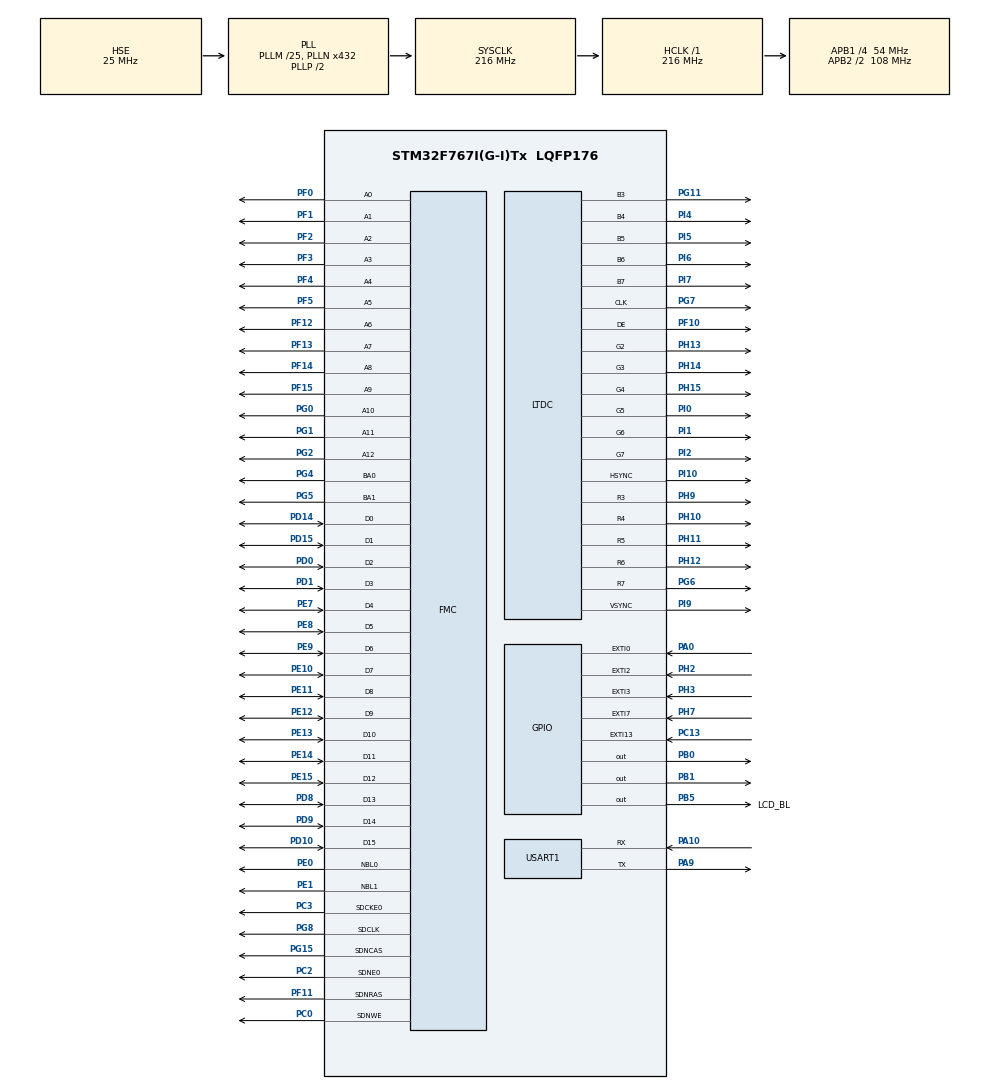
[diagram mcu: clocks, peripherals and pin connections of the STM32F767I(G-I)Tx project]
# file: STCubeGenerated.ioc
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CORTEX_M7.AccessPermission-Cortex_Memory_Protection_Unit_Region0_Settings=MPU_REGION_FULL_ACCESS
CORTEX_M7.BaseAddress-Cortex_Memory_Protection_Unit_Region0_Settings=0x60000000
CORTEX_M7.CPU_DCache=Enabled
CORTEX_M7.CPU_ICache=Enabled
CORTEX_M7.Enable-Cortex_Memory_Protection_Unit_Region0_Settings=MPU_REGION_ENABLE
CORTEX_M7.FlashInterface=TCM_Enabled
CORTEX_M7.IsBufferable-Cortex_Memory_Protection_Unit_Region0_Settings=MPU_ACCESS_BUFFERABLE
CORTEX_M7.MPU_Control=MPU_PRIVILEGED_DEFAULT
CORTEX_M7.Size-Cortex_Memory_Protection_Unit_Region0_Settings=MPU_REGION_SIZE_256MB
FMC.CASLatency1=FMC_SDRAM_CAS_LATENCY_3
FMC.ColumnBitsNumber1=FMC_SDRAM_COLUMN_BITS_NUM_9
FMC.ExitSelfRefreshDelay1=8
FMC.LoadToActiveDelay1=2
FMC.RCDDelay1=4
FMC.RPDelay1=2
FMC.ReadBurst1=FMC_SDRAM_RBURST_ENABLE
FMC.ReadPipeDelay1=FMC_SDRAM_RPIPE_DELAY_0
FMC.RowCycleDelay1=5
FMC.RowCycleDelay2=5
FMC.SDClockPeriod1=FMC_SDRAM_CLOCK_PERIOD_2
FMC.SelfRefreshTime1=6
FMC.WriteRecoveryTime1=2
LTDC.ActiveH=LCD_HEIGHT
LTDC.ActiveW=LCD_WIDTH
LTDC.Alpha_L0=255
LTDC.FBStartAdress_L0=LAYER0_ADDR
LTDC.FBStartAdress_L1=LAYER1_ADDR
LTDC.HBP=40
LTDC.HFP=5
LTDC.HSync=1
LTDC.ImageHeight_L0=LCD_HEIGHT
LTDC.ImageHeight_L1=LCD_HEIGHT
LTDC.ImageWidth_L0=LCD_WIDTH
LTDC.ImageWidth_L1=LCD_WIDTH
LTDC.Layers=1
LTDC.PixelFormat_L0=LTDC_PIXEL_FORMAT_RGB565
LTDC.PixelFormat_L1=LTDC_PIXEL_FORMAT_RGB565
LTDC.VBP=8
LTDC.VFP=8
LTDC.VSync=1
LTDC.WindowX1_L0=LCD_WIDTH
LTDC.WindowX1_L1=LCD_WIDTH
LTDC.WindowY1_L0=LCD_HEIGHT
LTDC.WindowY1_L1=LCD_HEIGHT
Mcu.Family=STM32F7
Mcu.Name=STM32F767I(G-I)Tx
Mcu.Package=LQFP176
Mcu.UserConstants=LAYER1_ADDR,0xC003FC00;LAYER0_ADDR,0xC0000000;LCD_WIDTH,480;LCD_HEIGHT,272
NVIC.EXTI0_IRQn=true\:0\:0\:false\:false\:true\:true\:true
NVIC.EXTI15_10_IRQn=true\:0\:0\:false\:false\:true\:true\:true
NVIC.EXTI2_IRQn=true\:0\:0\:false\:false\:true\:true\:true
NVIC.EXTI3_IRQn=true\:0\:0\:false\:false\:true\:true\:true
NVIC.EXTI9_5_IRQn=true\:0\:0\:false\:false\:true\:true\:true
NVIC.PriorityGroup=NVIC_PRIORITYGROUP_4
NVIC.USART1_IRQn=true\:0\:0\:false\:false\:true\:true\:true
PA0/WKUP.GPIO_PuPd=GPIO_PULLDOWN
PA0/WKUP.Signal=GPXTI0
PA10.Mode=Asynchronous
PA10.Signal=USART1_RX
PA13.Mode=Serial_Wire
PA13.Signal=SYS_JTMS-SWDIO
PA14.Mode=Serial_Wire
PA14.Signal=SYS_JTCK-SWCLK
PA9.Mode=Asynchronous
PA9.Signal=USART1_TX
PB0.Signal=GPIO_Output
PB1.Signal=GPIO_Output
PB5.GPIO_Label=LCD_BL
PB5.GPIO_Speed=GPIO_SPEED_FREQ_LOW
PB5.PinState=GPIO_PIN_SET
PB5.Signal=GPIO_Output
PC0.Signal=FMC_SDNWE
PC13.GPIO_ModeDefaultEXTI=GPIO_MODE_IT_FALLING
PC13.GPIO_PuPd=GPIO_PULLUP
PC13.Signal=GPXTI13
PC2.Mode=SdramChipSelect1_1
PC2.Signal=FMC_SDNE0
PC3.Mode=SdramChipSelect1_1
PC3.Signal=FMC_SDCKE0
PD0.Signal=FMC_D2_DA2
PD1.Signal=FMC_D3_DA3
PD10.Signal=FMC_D15_DA15
PD14.Signal=FMC_D0_DA0
PD15.Signal=FMC_D1_DA1
PD8.Signal=FMC_D13_DA13
PD9.Signal=FMC_D14_DA14
PE0.Signal=FMC_NBL0
PE1.Signal=FMC_NBL1
PE10.Signal=FMC_D7_DA7
PE11.Signal=FMC_D8_DA8
PE12.Signal=FMC_D9_DA9
PE13.Signal=FMC_D10_DA10
PE14.Signal=FMC_D11_DA11
PE15.Signal=FMC_D12_DA12
PE7.Signal=FMC_D4_DA4
PE8.Signal=FMC_D5_DA5
PE9.Signal=FMC_D6_DA6
PF0.Signal=FMC_A0
PF1.Signal=FMC_A1
PF10.GPIO_Speed=GPIO_SPEED_FREQ_VERY_HIGH
PF10.Mode=RGB565
PF10.Signal=LTDC_DE
PF11.Signal=FMC_SDNRAS
PF12.Signal=FMC_A6
PF13.Signal=FMC_A7
PF14.Signal=FMC_A8
PF15.Signal=FMC_A9
PF2.Signal=FMC_A2
PF3.Signal=FMC_A3
PF4.Signal=FMC_A4
PF5.Signal=FMC_A5
PG0.Signal=FMC_A10
PG1.Signal=FMC_A11
PG11.GPIO_Speed=GPIO_SPEED_FREQ_VERY_HIGH
PG11.Mode=RGB565
PG11.Signal=LTDC_B3
PG15.Signal=FMC_SDNCAS
PG2.Signal=FMC_A12
PG4.Signal=FMC_A14_BA0
PG5.Signal=FMC_A15_BA1
PG6.GPIO_Speed=GPIO_SPEED_FREQ_VERY_HIGH
PG6.Mode=RGB565
PG6.Signal=LTDC_R7
PG7.GPIO_Speed=GPIO_SPEED_FREQ_VERY_HIGH
PG7.Mode=RGB565
PG7.Signal=LTDC_CLK
PG8.Signal=FMC_SDCLK
PH0/OSC_IN.Mode=HSE-External-Oscillator
PH0/OSC_IN.Signal=RCC_OSC_IN
PH1/OSC_OUT.Mode=HSE-External-Oscillator
PH1/OSC_OUT.Signal=RCC_OSC_OUT
PH10.GPIO_Speed=GPIO_SPEED_FREQ_VERY_HIGH
PH10.Mode=RGB565
PH10.Signal=LTDC_R4
PH11.GPIO_Speed=GPIO_SPEED_FREQ_VERY_HIGH
PH11.Mode=RGB565
PH11.Signal=LTDC_R5
PH12.GPIO_Speed=GPIO_SPEED_FREQ_VERY_HIGH
PH12.Mode=RGB565
PH12.Signal=LTDC_R6
PH13.GPIO_Speed=GPIO_SPEED_FREQ_VERY_HIGH
PH13.Mode=RGB565
PH13.Signal=LTDC_G2
PH14.GPIO_Speed=GPIO_SPEED_FREQ_VERY_HIGH
PH14.Mode=RGB565
PH14.Signal=LTDC_G3
PH15.GPIO_Speed=GPIO_SPEED_FREQ_VERY_HIGH
PH15.Mode=RGB565
PH15.Signal=LTDC_G4
PH2.GPIO_ModeDefaultEXTI=GPIO_MODE_IT_FALLING
PH2.GPIO_PuPd=GPIO_PULLUP
PH2.Signal=GPXTI2
PH3.GPIO_ModeDefaultEXTI=GPIO_MODE_IT_FALLING
PH3.GPIO_PuPd=GPIO_PULLUP
PH3.Signal=GPXTI3
PH7.GPIO_ModeDefaultEXTI=GPIO_MODE_IT_FALLING
PH7.Signal=GPXTI7
PH9.GPIO_Speed=GPIO_SPEED_FREQ_VERY_HIGH
PH9.Mode=RGB565
PH9.Signal=LTDC_R3
PI0.GPIO_Speed=GPIO_SPEED_FREQ_VERY_HIGH
PI0.Mode=RGB565
PI0.Signal=LTDC_G5
PI1.GPIO_Speed=GPIO_SPEED_FREQ_VERY_HIGH
PI1.Mode=RGB565
PI1.Signal=LTDC_G6
PI10.GPIO_Speed=GPIO_SPEED_FREQ_VERY_HIGH
PI10.Mode=RGB565
PI10.Signal=LTDC_HSYNC
PI2.GPIO_Speed=GPIO_SPEED_FREQ_VERY_HIGH
PI2.Mode=RGB565
PI2.Signal=LTDC_G7
PI4.GPIO_Speed=GPIO_SPEED_FREQ_VERY_HIGH
PI4.Mode=RGB565
PI4.Signal=LTDC_B4
PI5.GPIO_Speed=GPIO_SPEED_FREQ_VERY_HIGH
PI5.Mode=RGB565
PI5.Signal=LTDC_B5
PI6.GPIO_Speed=GPIO_SPEED_FREQ_VERY_HIGH
PI6.Mode=RGB565
PI6.Signal=LTDC_B6
PI7.GPIO_Speed=GPIO_SPEED_FREQ_VERY_HIGH
PI7.Mode=RGB565
PI7.Signal=LTDC_B7
PI9.GPIO_Speed=GPIO_SPEED_FREQ_VERY_HIGH
PI9.Mode=RGB565
PI9.Signal=LTDC_VSYNC
ProjectManager.HeapSize=0x200
ProjectManager.StackSize=0x400
ProjectManager.TargetToolchain=Other Toolchains (GPDSC)
RCC.AHBFreq_Value=216000000
RCC.APB1CLKDivider=RCC_HCLK_DIV4
RCC.APB1Freq_Value=54000000
RCC.APB1TimFreq_Value=108000000
RCC.APB2CLKDivider=RCC_HCLK_DIV2
RCC.APB2Freq_Value=108000000
RCC.APB2TimFreq_Value=216000000
RCC.CortexFreq_Value=216000000
RCC.EnbaleCSS=true
RCC.HCLKFreq_Value=216000000
RCC.HSE_VALUE=25000000
RCC.HSI_VALUE=16000000
RCC.LSE_VALUE=32768
RCC.PLLM=25
RCC.PLLN=432
RCC.PLLSAIN=288
RCC.PLLSAIR=4
RCC.PLLSAIRDiv=RCC_PLLSAIDIVR_8
RCC.PLLSourceVirtual=RCC_PLLSOURCE_HSE
RCC.SYSCLKFreq_VALUE=216000000
RCC.SYSCLKSource=RCC_SYSCLKSOURCE_PLLCLK
RCC.USBFreq_Value=216000000
RCC.VCOOutputFreq_Value=432000000
SH.FMC_A0.0=FMC_A0,13b-sda1
SH.FMC_A1.0=FMC_A1,13b-sda1
SH.FMC_A10.0=FMC_A10,13b-sda1
SH.FMC_A11.0=FMC_A11,13b-sda1
SH.FMC_A12.0=FMC_A12,13b-sda1
SH.FMC_A14_BA0.0=FMC_BA0,FourSdramBanks1
SH.FMC_A15_BA1.0=FMC_BA1,FourSdramBanks1
SH.FMC_A2.0=FMC_A2,13b-sda1
SH.FMC_A3.0=FMC_A3,13b-sda1
SH.FMC_A4.0=FMC_A4,13b-sda1
SH.FMC_A5.0=FMC_A5,13b-sda1
SH.FMC_A6.0=FMC_A6,13b-sda1
SH.FMC_A7.0=FMC_A7,13b-sda1
SH.FMC_A8.0=FMC_A8,13b-sda1
SH.FMC_A9.0=FMC_A9,13b-sda1
SH.FMC_D0_DA0.0=FMC_D0,sd-16b-d1
SH.FMC_D10_DA10.0=FMC_D10,sd-16b-d1
SH.FMC_D11_DA11.0=FMC_D11,sd-16b-d1
SH.FMC_D12_DA12.0=FMC_D12,sd-16b-d1
SH.FMC_D13_DA13.0=FMC_D13,sd-16b-d1
SH.FMC_D14_DA14.0=FMC_D14,sd-16b-d1
SH.FMC_D15_DA15.0=FMC_D15,sd-16b-d1
SH.FMC_D1_DA1.0=FMC_D1,sd-16b-d1
SH.FMC_D2_DA2.0=FMC_D2,sd-16b-d1
SH.FMC_D3_DA3.0=FMC_D3,sd-16b-d1
SH.FMC_D4_DA4.0=FMC_D4,sd-16b-d1
SH.FMC_D5_DA5.0=FMC_D5,sd-16b-d1
SH.FMC_D6_DA6.0=FMC_D6,sd-16b-d1
SH.FMC_D7_DA7.0=FMC_D7,sd-16b-d1
SH.FMC_D8_DA8.0=FMC_D8,sd-16b-d1
SH.FMC_D9_DA9.0=FMC_D9,sd-16b-d1
SH.FMC_NBL0.0=FMC_NBL0,Sd2ByteEnable1
SH.FMC_NBL1.0=FMC_NBL1,Sd2ByteEnable1
SH.FMC_SDCLK.0=FMC_SDCLK,13b-sda1
SH.FMC_SDNCAS.0=FMC_SDNCAS,13b-sda1
SH.FMC_SDNRAS.0=FMC_SDNRAS,13b-sda1
SH.FMC_SDNWE.0=FMC_SDNWE,13b-sda1
USART1.VirtualMode-Asynchronous=VM_ASYNC
VP_CRC_VS_CRC.Mode=CRC_Activate
board=custom

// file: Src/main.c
/* USER CODE BEGIN Header */
/**
  ******************************************************************************
  * @file           : main.c
  * @brief          : Main program body
  ******************************************************************************
  * @attention
  *
  * <h2><center>&copy; Copyright (c) 2019 STMicroelectronics.
  * All rights reserved.</center></h2>
  *
  * This software component is licensed by ST under BSD 3-Clause license,
  * the "License"; You may not use this file except in compliance with the
  * License. You may obtain a copy of the License at:
  *                        opensource.org/licenses/BSD-3-Clause
  *
  ******************************************************************************
  */
/* USER CODE END Header */

#include "main.h"

CRC_HandleTypeDef hcrc;

LTDC_HandleTypeDef hltdc;

UART_HandleTypeDef huart1;

SDRAM_HandleTypeDef hsdram1;

void SystemClock_Config(void);
static void MPU_Config(void);
static void MX_GPIO_Init(void);
static void MX_USART1_UART_Init(void);
static void MX_CRC_Init(void);
static void MX_FMC_Init(void);
static void MX_LTDC_Init(void);

int main(void)
{

  /* MPU Configuration--------------------------------------------------------*/
  MPU_Config();

  /* Enable I-Cache---------------------------------------------------------*/
  SCB_EnableICache();

  /* Enable D-Cache---------------------------------------------------------*/
  SCB_EnableDCache();

  /* MCU Configuration--------------------------------------------------------*/

  /* Reset of all peripherals, Initializes the Flash interface and the Systick. */
  HAL_Init();

  /* USER CODE BEGIN Init */
  SCB->CACR |= 1<<2;   //强制D-Cache透写,如不开启,实际使用中可能遇到各种问题
  /* USER CODE END Init */

  /* Configure the system clock */
  SystemClock_Config();

  /* Initialize all configured peripherals */
  MX_GPIO_Init();
  MX_USART1_UART_Init();
  MX_CRC_Init();
  MX_FMC_Init();
  MX_LTDC_Init();
  /* USER CODE BEGIN 2 */
  os_init();
  /* USER CODE END 2 */

  /* Infinite loop */
  while (1)
  {

  }
}

void SystemClock_Config(void)
{
  RCC_OscInitTypeDef RCC_OscInitStruct = {0};
  RCC_ClkInitTypeDef RCC_ClkInitStruct = {0};
  RCC_PeriphCLKInitTypeDef PeriphClkInitStruct = {0};

  /** Configure the main internal regulator output voltage
  */
  __HAL_RCC_PWR_CLK_ENABLE();
  __HAL_PWR_VOLTAGESCALING_CONFIG(PWR_REGULATOR_VOLTAGE_SCALE1);
  /** Initializes the CPU, AHB and APB busses clocks
  */
  RCC_OscInitStruct.OscillatorType = RCC_OSCILLATORTYPE_HSE;
  RCC_OscInitStruct.HSEState = RCC_HSE_ON;
  RCC_OscInitStruct.PLL.PLLState = RCC_PLL_ON;
  RCC_OscInitStruct.PLL.PLLSource = RCC_PLLSOURCE_HSE;
  RCC_OscInitStruct.PLL.PLLM = 25;
  RCC_OscInitStruct.PLL.PLLN = 432;
  RCC_OscInitStruct.PLL.PLLP = RCC_PLLP_DIV2;
  RCC_OscInitStruct.PLL.PLLQ = 2;
  if (HAL_RCC_OscConfig(&RCC_OscInitStruct) != HAL_OK)
  {
    Error_Handler();
  }
  /** Activate the Over-Drive mode
  */
  if (HAL_PWREx_EnableOverDrive() != HAL_OK)
  {
    Error_Handler();
  }
  /** Initializes the CPU, AHB and APB busses clocks
  */
  RCC_ClkInitStruct.ClockType = RCC_CLOCKTYPE_HCLK|RCC_CLOCKTYPE_SYSCLK
                              |RCC_CLOCKTYPE_PCLK1|RCC_CLOCKTYPE_PCLK2;
  RCC_ClkInitStruct.SYSCLKSource = RCC_SYSCLKSOURCE_PLLCLK;
  RCC_ClkInitStruct.AHBCLKDivider = RCC_SYSCLK_DIV1;
  RCC_ClkInitStruct.APB1CLKDivider = RCC_HCLK_DIV4;
  RCC_ClkInitStruct.APB2CLKDivider = RCC_HCLK_DIV2;

  if (HAL_RCC_ClockConfig(&RCC_ClkInitStruct, FLASH_LATENCY_7) != HAL_OK)
  {
    Error_Handler();
  }
  PeriphClkInitStruct.PeriphClockSelection = RCC_PERIPHCLK_LTDC|RCC_PERIPHCLK_USART1;
  PeriphClkInitStruct.PLLSAI.PLLSAIN = 288;
  PeriphClkInitStruct.PLLSAI.PLLSAIR = 4;
  PeriphClkInitStruct.PLLSAI.PLLSAIQ = 2;
  PeriphClkInitStruct.PLLSAI.PLLSAIP = RCC_PLLSAIP_DIV2;
  PeriphClkInitStruct.PLLSAIDivQ = 1;
  PeriphClkInitStruct.PLLSAIDivR = RCC_PLLSAIDIVR_8;
  PeriphClkInitStruct.Usart1ClockSelection = RCC_USART1CLKSOURCE_PCLK2;
  if (HAL_RCCEx_PeriphCLKConfig(&PeriphClkInitStruct) != HAL_OK)
  {
    Error_Handler();
  }
  /** Enables the Clock Security System
  */
  HAL_RCC_EnableCSS();
}

static void MX_CRC_Init(void)
{

  hcrc.Instance = CRC;
  hcrc.Init.DefaultPolynomialUse = DEFAULT_POLYNOMIAL_ENABLE;
  hcrc.Init.DefaultInitValueUse = DEFAULT_INIT_VALUE_ENABLE;
  hcrc.Init.InputDataInversionMode = CRC_INPUTDATA_INVERSION_NONE;
  hcrc.Init.OutputDataInversionMode = CRC_OUTPUTDATA_INVERSION_DISABLE;
  hcrc.InputDataFormat = CRC_INPUTDATA_FORMAT_BYTES;
  if (HAL_CRC_Init(&hcrc) != HAL_OK)
  {
    Error_Handler();
  }

}

static void MX_LTDC_Init(void)
{

  LTDC_LayerCfgTypeDef pLayerCfg = {0};
  LTDC_LayerCfgTypeDef pLayerCfg1 = {0};

  hltdc.Instance = LTDC;
  hltdc.Init.HSPolarity = LTDC_HSPOLARITY_AL;
  hltdc.Init.VSPolarity = LTDC_VSPOLARITY_AL;
  hltdc.Init.DEPolarity = LTDC_DEPOLARITY_AL;
  hltdc.Init.PCPolarity = LTDC_PCPOLARITY_IPC;
  hltdc.Init.HorizontalSync = 0;
  hltdc.Init.VerticalSync = 0;
  hltdc.Init.AccumulatedHBP = 40;
  hltdc.Init.AccumulatedVBP = 8;
  hltdc.Init.AccumulatedActiveW = 520;
  hltdc.Init.AccumulatedActiveH = 280;
  hltdc.Init.TotalWidth = 525;
  hltdc.Init.TotalHeigh = 288;
  hltdc.Init.Backcolor.Blue = 0;
  hltdc.Init.Backcolor.Green = 0;
  hltdc.Init.Backcolor.Red = 0;
  if (HAL_LTDC_Init(&hltdc) != HAL_OK)
  {
    Error_Handler();
  }
  pLayerCfg.WindowX0 = 0;
  pLayerCfg.WindowX1 = LCD_WIDTH;
  pLayerCfg.WindowY0 = 0;
  pLayerCfg.WindowY1 = LCD_HEIGHT;
  pLayerCfg.PixelFormat = LTDC_PIXEL_FORMAT_RGB565;
  pLayerCfg.Alpha = 255;
  pLayerCfg.Alpha0 = 0;
  pLayerCfg.BlendingFactor1 = LTDC_BLENDING_FACTOR1_CA;
  pLayerCfg.BlendingFactor2 = LTDC_BLENDING_FACTOR2_CA;
  pLayerCfg.FBStartAdress = LAYER0_ADDR;
  pLayerCfg.ImageWidth = LCD_WIDTH;
  pLayerCfg.ImageHeight = LCD_HEIGHT;
  pLayerCfg.Backcolor.Blue = 0;
  pLayerCfg.Backcolor.Green = 0;
  pLayerCfg.Backcolor.Red = 0;
  if (HAL_LTDC_ConfigLayer(&hltdc, &pLayerCfg, 0) != HAL_OK)
  {
    Error_Handler();
  }
  pLayerCfg1.WindowX0 = 0;
  pLayerCfg1.WindowX1 = LCD_WIDTH;
  pLayerCfg1.WindowY0 = 0;
  pLayerCfg1.WindowY1 = LCD_HEIGHT;
  pLayerCfg1.PixelFormat = LTDC_PIXEL_FORMAT_ARGB8888;
  pLayerCfg1.Alpha = 0;
  pLayerCfg1.Alpha0 = 0;
  pLayerCfg1.BlendingFactor1 = LTDC_BLENDING_FACTOR1_CA;
  pLayerCfg1.BlendingFactor2 = LTDC_BLENDING_FACTOR2_CA;
  pLayerCfg1.FBStartAdress = LAYER1_ADDR;
  pLayerCfg1.ImageWidth = LCD_WIDTH;
  pLayerCfg1.ImageHeight = LCD_HEIGHT;
  pLayerCfg1.Backcolor.Blue = 0;
  pLayerCfg1.Backcolor.Green = 0;
  pLayerCfg1.Backcolor.Red = 0;
  if (HAL_LTDC_ConfigLayer(&hltdc, &pLayerCfg1, 1) != HAL_OK)
  {
    Error_Handler();
  }

}

static void MX_USART1_UART_Init(void)
{

  huart1.Instance = USART1;
  huart1.Init.BaudRate = 115200;
  huart1.Init.WordLength = UART_WORDLENGTH_8B;
  huart1.Init.StopBits = UART_STOPBITS_1;
  huart1.Init.Parity = UART_PARITY_NONE;
  huart1.Init.Mode = UART_MODE_TX_RX;
  huart1.Init.HwFlowCtl = UART_HWCONTROL_NONE;
  huart1.Init.OverSampling = UART_OVERSAMPLING_16;
  huart1.Init.OneBitSampling = UART_ONE_BIT_SAMPLE_DISABLE;
  huart1.AdvancedInit.AdvFeatureInit = UART_ADVFEATURE_NO_INIT;
  if (HAL_UART_Init(&huart1) != HAL_OK)
  {
    Error_Handler();
  }

}

/* FMC initialization function */
static void MX_FMC_Init(void)
{

  FMC_SDRAM_TimingTypeDef SdramTiming = {0};

  /** Perform the SDRAM1 memory initialization sequence
  */
  hsdram1.Instance = FMC_SDRAM_DEVICE;
  /* hsdram1.Init */
  hsdram1.Init.SDBank = FMC_SDRAM_BANK1;
  hsdram1.Init.ColumnBitsNumber = FMC_SDRAM_COLUMN_BITS_NUM_9;
  hsdram1.Init.RowBitsNumber = FMC_SDRAM_ROW_BITS_NUM_13;
  hsdram1.Init.MemoryDataWidth = FMC_SDRAM_MEM_BUS_WIDTH_16;
  hsdram1.Init.InternalBankNumber = FMC_SDRAM_INTERN_BANKS_NUM_4;
  hsdram1.Init.CASLatency = FMC_SDRAM_CAS_LATENCY_3;
  hsdram1.Init.WriteProtection = FMC_SDRAM_WRITE_PROTECTION_DISABLE;
  hsdram1.Init.SDClockPeriod = FMC_SDRAM_CLOCK_PERIOD_2;
  hsdram1.Init.ReadBurst = FMC_SDRAM_RBURST_ENABLE;
  hsdram1.Init.ReadPipeDelay = FMC_SDRAM_RPIPE_DELAY_0;
  /* SdramTiming */
  SdramTiming.LoadToActiveDelay = 2;
  SdramTiming.ExitSelfRefreshDelay = 8;
  SdramTiming.SelfRefreshTime = 6;
  SdramTiming.RowCycleDelay = 5;
  SdramTiming.WriteRecoveryTime = 2;
  SdramTiming.RPDelay = 2;
  SdramTiming.RCDDelay = 4;

  if (HAL_SDRAM_Init(&hsdram1, &SdramTiming) != HAL_OK)
  {
    Error_Handler( );
  }

}

static void MX_GPIO_Init(void)
{
  GPIO_InitTypeDef GPIO_InitStruct = {0};

  /* GPIO Ports Clock Enable */
  __HAL_RCC_GPIOC_CLK_ENABLE();
  __HAL_RCC_GPIOI_CLK_ENABLE();
  __HAL_RCC_GPIOF_CLK_ENABLE();
  __HAL_RCC_GPIOH_CLK_ENABLE();
  __HAL_RCC_GPIOA_CLK_ENABLE();
  __HAL_RCC_GPIOB_CLK_ENABLE();
  __HAL_RCC_GPIOG_CLK_ENABLE();
  __HAL_RCC_GPIOE_CLK_ENABLE();
  __HAL_RCC_GPIOD_CLK_ENABLE();

  /*Configure GPIO pin Output Level */
  HAL_GPIO_WritePin(GPIOB, GPIO_PIN_0|GPIO_PIN_1, GPIO_PIN_RESET);

  /*Configure GPIO pin Output Level */
  HAL_GPIO_WritePin(LCD_BL_GPIO_Port, LCD_BL_Pin, GPIO_PIN_SET);

  /*Configure GPIO pin : PC13 */
  GPIO_InitStruct.Pin = GPIO_PIN_13;
  GPIO_InitStruct.Mode = GPIO_MODE_IT_FALLING;
  GPIO_InitStruct.Pull = GPIO_PULLUP;
  HAL_GPIO_Init(GPIOC, &GPIO_InitStruct);

  /*Configure GPIO pin : PA0 */
  GPIO_InitStruct.Pin = GPIO_PIN_0;
  GPIO_InitStruct.Mode = GPIO_MODE_IT_RISING;
  GPIO_InitStruct.Pull = GPIO_PULLDOWN;
  HAL_GPIO_Init(GPIOA, &GPIO_InitStruct);

  /*Configure GPIO pins : PH2 PH3 */
  GPIO_InitStruct.Pin = GPIO_PIN_2|GPIO_PIN_3;
  GPIO_InitStruct.Mode = GPIO_MODE_IT_FALLING;
  GPIO_InitStruct.Pull = GPIO_PULLUP;
  HAL_GPIO_Init(GPIOH, &GPIO_InitStruct);

  /*Configure GPIO pins : PB0 PB1 LCD_BL_Pin */
  GPIO_InitStruct.Pin = GPIO_PIN_0|GPIO_PIN_1|LCD_BL_Pin;
  GPIO_InitStruct.Mode = GPIO_MODE_OUTPUT_PP;
  GPIO_InitStruct.Pull = GPIO_NOPULL;
  GPIO_InitStruct.Speed = GPIO_SPEED_FREQ_LOW;
  HAL_GPIO_Init(GPIOB, &GPIO_InitStruct);

  /*Configure GPIO pin : PH7 */
  GPIO_InitStruct.Pin = GPIO_PIN_7;
  GPIO_InitStruct.Mode = GPIO_MODE_IT_RISING;
  GPIO_InitStruct.Pull = GPIO_NOPULL;
  HAL_GPIO_Init(GPIOH, &GPIO_InitStruct);

  /* EXTI interrupt init*/
  HAL_NVIC_SetPriority(EXTI0_IRQn, 0, 0);
  HAL_NVIC_EnableIRQ(EXTI0_IRQn);

  HAL_NVIC_SetPriority(EXTI2_IRQn, 0, 0);
  HAL_NVIC_EnableIRQ(EXTI2_IRQn);

  HAL_NVIC_SetPriority(EXTI3_IRQn, 0, 0);
  HAL_NVIC_EnableIRQ(EXTI3_IRQn);

  HAL_NVIC_SetPriority(EXTI9_5_IRQn, 0, 0);
  HAL_NVIC_EnableIRQ(EXTI9_5_IRQn);

  HAL_NVIC_SetPriority(EXTI15_10_IRQn, 0, 0);
  HAL_NVIC_EnableIRQ(EXTI15_10_IRQn);
}

/* MPU Configuration */

void MPU_Config(void)
{
  MPU_Region_InitTypeDef MPU_InitStruct = {0};

  /* Disables the MPU */
  HAL_MPU_Disable();
  /** Initializes and configures the Region and the memory to be protected
  */
  MPU_InitStruct.Enable = MPU_REGION_ENABLE;
  MPU_InitStruct.Number = MPU_REGION_NUMBER0;
  MPU_InitStruct.BaseAddress = 0x60000000;
  MPU_InitStruct.Size = MPU_REGION_SIZE_256MB;
  MPU_InitStruct.SubRegionDisable = 0x0;
  MPU_InitStruct.TypeExtField = MPU_TEX_LEVEL0;
  MPU_InitStruct.AccessPermission = MPU_REGION_FULL_ACCESS;
  MPU_InitStruct.DisableExec = MPU_INSTRUCTION_ACCESS_ENABLE;
  MPU_InitStruct.IsShareable = MPU_ACCESS_NOT_SHAREABLE;
  MPU_InitStruct.IsCacheable = MPU_ACCESS_NOT_CACHEABLE;
  MPU_InitStruct.IsBufferable = MPU_ACCESS_BUFFERABLE;

  HAL_MPU_ConfigRegion(&MPU_InitStruct);
  /* Enables the MPU */
  HAL_MPU_Enable(MPU_PRIVILEGED_DEFAULT);

}

void Error_Handler(void)
{
}

/************************ (C) COPYRIGHT STMicroelectronics *****END OF FILE****/
